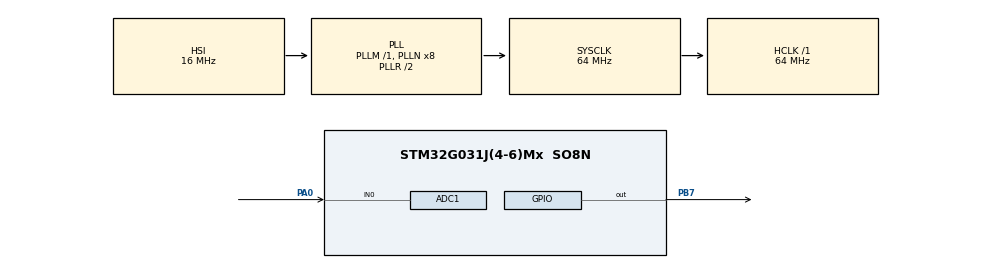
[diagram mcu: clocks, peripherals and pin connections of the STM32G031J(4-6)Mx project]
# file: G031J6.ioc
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ADC1.Channel-0\#ChannelRegularConversion=ADC_CHANNEL_0
ADC1.NbrOfConversionFlag=1
ADC1.Rank-0\#ChannelRegularConversion=1
ADC1.SamplingTime-0\#ChannelRegularConversion=ADC_SAMPLINGTIME_COMMON_1
ADC1.master=1
Mcu.Family=STM32G0
Mcu.Name=STM32G031J(4-6)Mx
Mcu.Package=SO8N
PA0.Mode=IN0
PA0.Signal=ADC1_IN0
PA13.Mode=Serial_Wire
PA13.Signal=SYS_SWDIO
PA14-BOOT0.Mode=Serial_Wire
PA14-BOOT0.Signal=SYS_SWCLK
PB7.Signal=GPIO_Output
ProjectManager.HeapSize=0x200
ProjectManager.StackSize=0x400
ProjectManager.TargetToolchain=MDK-ARM V5.32
RCC.ADCFreq_Value=64000000
RCC.AHBFreq_Value=64000000
RCC.CortexFreq_Value=64000000
RCC.EXTERNAL_CLOCK_VALUE=12288000
RCC.HCLKFreq_Value=64000000
RCC.HSE_VALUE=8000000
RCC.HSI_VALUE=16000000
RCC.LSE_VALUE=32768
RCC.SYSCLKFreq_VALUE=64000000
RCC.SYSCLKSource=RCC_SYSCLKSOURCE_PLLCLK
RCC.VCOOutputFreq_Value=128000000
VP_SYS_VS_PIN1REMAP.Mode=PIN1REMAP
board=custom

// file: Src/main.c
/* USER CODE BEGIN Header */
/**
  ******************************************************************************
  * @file           : main.c
  * @brief          : Main program body
  ******************************************************************************
  * @attention
  *
  * <h2><center>&copy; Copyright (c) 2020 STMicroelectronics.
  * All rights reserved.</center></h2>
  *
  * This software component is licensed by ST under BSD 3-Clause license,
  * the "License"; You may not use this file except in compliance with the
  * License. You may obtain a copy of the License at:
  *                        opensource.org/licenses/BSD-3-Clause
  *
  ******************************************************************************
  */
/* USER CODE END Header */

#include "main.h"
#include "adc.h"
#include "gpio.h"

void SystemClock_Config(void);

/* USER CODE BEGIN 0 */
uint16_t AD_Value,Vol_Value;
/* USER CODE END 0 */

int main(void)
{

  /* MCU Configuration--------------------------------------------------------*/

  /* Reset of all peripherals, Initializes the Flash interface and the Systick. */
  HAL_Init();

  /* Configure the system clock */
  SystemClock_Config();

  /* Initialize all configured peripherals */
  MX_GPIO_Init();
  MX_ADC1_Init();

  /* Infinite loop */
  while (1)
  {

    /* USER CODE BEGIN 3 */
		HAL_ADC_Start(&hadc1);
		HAL_ADC_PollForConversion(&hadc1, 100);
	if(HAL_IS_BIT_SET(HAL_ADC_GetState(&hadc1), HAL_ADC_STATE_REG_EOC))
	{
		AD_Value = HAL_ADC_GetValue(&hadc1);
		Vol_Value=(AD_Value*3300)/4096;

	}

	HAL_Delay(100);
  }
  /* USER CODE END 3 */
}

void SystemClock_Config(void)
{
  RCC_OscInitTypeDef RCC_OscInitStruct = {0};
  RCC_ClkInitTypeDef RCC_ClkInitStruct = {0};
  RCC_PeriphCLKInitTypeDef PeriphClkInit = {0};

  /** Configure the main internal regulator output voltage
  */
  HAL_PWREx_ControlVoltageScaling(PWR_REGULATOR_VOLTAGE_SCALE1);
  /** Initializes the CPU, AHB and APB busses clocks
  */
  RCC_OscInitStruct.OscillatorType = RCC_OSCILLATORTYPE_HSI;
  RCC_OscInitStruct.HSIState = RCC_HSI_ON;
  RCC_OscInitStruct.HSIDiv = RCC_HSI_DIV1;
  RCC_OscInitStruct.HSICalibrationValue = RCC_HSICALIBRATION_DEFAULT;
  RCC_OscInitStruct.PLL.PLLState = RCC_PLL_ON;
  RCC_OscInitStruct.PLL.PLLSource = RCC_PLLSOURCE_HSI;
  RCC_OscInitStruct.PLL.PLLM = RCC_PLLM_DIV1;
  RCC_OscInitStruct.PLL.PLLN = 8;
  RCC_OscInitStruct.PLL.PLLP = RCC_PLLP_DIV2;
  RCC_OscInitStruct.PLL.PLLQ = RCC_PLLQ_DIV2;
  RCC_OscInitStruct.PLL.PLLR = RCC_PLLR_DIV2;
  if (HAL_RCC_OscConfig(&RCC_OscInitStruct) != HAL_OK)
  {
    Error_Handler();
  }
  /** Initializes the CPU, AHB and APB busses clocks
  */
  RCC_ClkInitStruct.ClockType = RCC_CLOCKTYPE_HCLK|RCC_CLOCKTYPE_SYSCLK
                              |RCC_CLOCKTYPE_PCLK1;
  RCC_ClkInitStruct.SYSCLKSource = RCC_SYSCLKSOURCE_PLLCLK;
  RCC_ClkInitStruct.AHBCLKDivider = RCC_SYSCLK_DIV1;
  RCC_ClkInitStruct.APB1CLKDivider = RCC_HCLK_DIV1;

  if (HAL_RCC_ClockConfig(&RCC_ClkInitStruct, FLASH_LATENCY_2) != HAL_OK)
  {
    Error_Handler();
  }
  /** Initializes the peripherals clocks
  */
  PeriphClkInit.PeriphClockSelection = RCC_PERIPHCLK_ADC;
  PeriphClkInit.AdcClockSelection = RCC_ADCCLKSOURCE_SYSCLK;
  if (HAL_RCCEx_PeriphCLKConfig(&PeriphClkInit) != HAL_OK)
  {
    Error_Handler();
  }
}

void Error_Handler(void)
{
}

/************************ (C) COPYRIGHT STMicroelectronics *****END OF FILE****/
